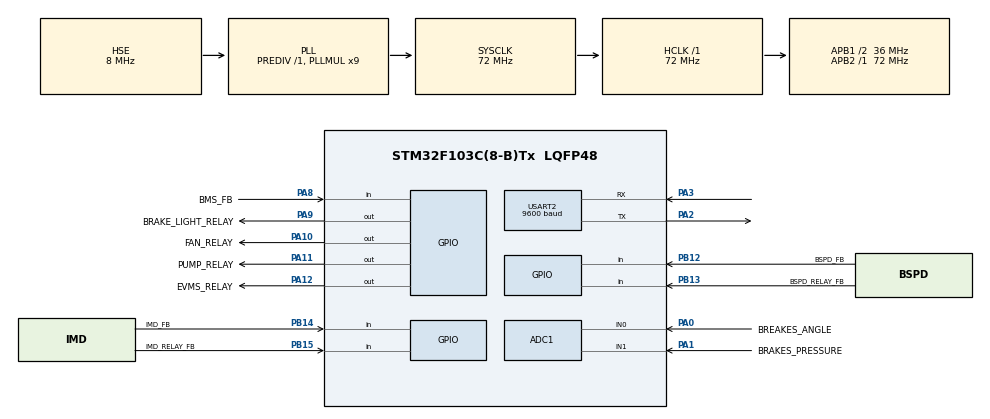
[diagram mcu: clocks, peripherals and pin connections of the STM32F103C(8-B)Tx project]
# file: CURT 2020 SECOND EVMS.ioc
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ADC1.Channel-0\#ChannelRegularConversion=ADC_CHANNEL_0
ADC1.Channel-1\#ChannelRegularConversion=ADC_CHANNEL_1
ADC1.ContinuousConvMode=ENABLE
ADC1.NbrOfConversion=2
ADC1.NbrOfConversionFlag=1
ADC1.Rank-0\#ChannelRegularConversion=1
ADC1.Rank-1\#ChannelRegularConversion=2
ADC1.SamplingTime-0\#ChannelRegularConversion=ADC_SAMPLETIME_71CYCLES_5
ADC1.SamplingTime-1\#ChannelRegularConversion=ADC_SAMPLETIME_71CYCLES_5
ADC1.master=1
Dma.ADC1.0.Direction=DMA_PERIPH_TO_MEMORY
Dma.ADC1.0.Instance=DMA1_Channel1
Dma.ADC1.0.MemDataAlignment=DMA_MDATAALIGN_HALFWORD
Dma.ADC1.0.MemInc=DMA_MINC_ENABLE
Dma.ADC1.0.Mode=DMA_CIRCULAR
Dma.ADC1.0.PeriphDataAlignment=DMA_PDATAALIGN_HALFWORD
Dma.ADC1.0.PeriphInc=DMA_PINC_DISABLE
Dma.ADC1.0.Priority=DMA_PRIORITY_LOW
Dma.Request0=ADC1
Mcu.Family=STM32F1
Mcu.Name=STM32F103C(8-B)Tx
Mcu.Package=LQFP48
NVIC.DMA1_Channel1_IRQn=true\:0\:0\:false\:false\:true\:false\:true
NVIC.PriorityGroup=NVIC_PRIORITYGROUP_4
PA0-WKUP.GPIO_Label=BREAKES_ANGLE
PA0-WKUP.Signal=ADCx_IN0
PA1.GPIO_Label=BRAKES_PRESSURE
PA1.Signal=ADCx_IN1
PA10.GPIO_Label=FAN_RELAY
PA10.Signal=GPIO_Output
PA11.GPIO_Label=PUMP_RELAY
PA11.Signal=GPIO_Output
PA12.GPIO_Label=EVMS_RELAY
PA12.Signal=GPIO_Output
PA2.Mode=Asynchronous
PA2.Signal=USART2_TX
PA3.Mode=Asynchronous
PA3.Signal=USART2_RX
PA8.GPIO_Label=BMS_FB
PA8.Signal=GPIO_Input
PA9.GPIO_Label=BRAKE_LIGHT_RELAY
PA9.Signal=GPIO_Output
PB12.GPIO_Label=BSPD_FB
PB12.Signal=GPIO_Input
PB13.GPIO_Label=BSPD_RELAY_FB
PB13.Signal=GPIO_Input
PB14.GPIO_Label=IMD_FB
PB14.Signal=GPIO_Input
PB15.GPIO_Label=IMD_RELAY_FB
PB15.Signal=GPIO_Input
PC14-OSC32_IN.Mode=LSE-External-Oscillator
PC14-OSC32_IN.Signal=RCC_OSC32_IN
PC15-OSC32_OUT.Mode=LSE-External-Oscillator
PC15-OSC32_OUT.Signal=RCC_OSC32_OUT
PD0-OSC_IN.Mode=HSE-External-Oscillator
PD0-OSC_IN.Signal=RCC_OSC_IN
PD1-OSC_OUT.Mode=HSE-External-Oscillator
PD1-OSC_OUT.Signal=RCC_OSC_OUT
ProjectManager.HeapSize=0x200
ProjectManager.StackSize=0x400
ProjectManager.TargetToolchain=TrueSTUDIO
RCC.ADCPresc=RCC_ADCPCLK2_DIV8
RCC.AHBFreq_Value=72000000
RCC.APB1CLKDivider=RCC_HCLK_DIV2
RCC.APB1Freq_Value=36000000
RCC.APB1TimFreq_Value=72000000
RCC.APB2Freq_Value=72000000
RCC.APB2TimFreq_Value=72000000
RCC.HCLKFreq_Value=72000000
RCC.PLLMUL=RCC_PLL_MUL9
RCC.PLLSourceVirtual=RCC_PLLSOURCE_HSE
RCC.SYSCLKFreq_VALUE=72000000
RCC.SYSCLKSource=RCC_SYSCLKSOURCE_PLLCLK
RCC.USBFreq_Value=72000000
SH.ADCx_IN0.0=ADC1_IN0,IN0
SH.ADCx_IN1.0=ADC1_IN1,IN1
USART2.BaudRate=9600
USART2.VirtualMode=VM_ASYNC
VP_SYS_VS_ND.Mode=No_Debug
board=custom

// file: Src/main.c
/* USER CODE BEGIN Header */
/**
  ******************************************************************************
  * @file           : main.c
  * @brief          : Main program body
  ******************************************************************************
  * @attention
  *
  * <h2><center>&copy; Copyright (c) 2021 STMicroelectronics.
  * All rights reserved.</center></h2>
  *
  * This software component is licensed by ST under BSD 3-Clause license,
  * the "License"; You may not use this file except in compliance with the
  * License. You may obtain a copy of the License at:
  *                        opensource.org/licenses/BSD-3-Clause
  *
  ******************************************************************************
  */
/* USER CODE END Header */

#include "main.h"
#include "EVMS2.h"

ADC_HandleTypeDef hadc1;
DMA_HandleTypeDef hdma_adc1;

UART_HandleTypeDef huart2;

void SystemClock_Config(void);
static void MX_GPIO_Init(void);
static void MX_ADC1_Init(void);
static void MX_USART2_UART_Init(void);
static void MX_DMA_Init(void);

int main(void)
{

  /* MCU Configuration--------------------------------------------------------*/

  /* Reset of all peripherals, Initializes the Flash interface and the Systick. */
  HAL_Init();

  /* Configure the system clock */
  SystemClock_Config();

  /* Initialize all configured peripherals */
  MX_GPIO_Init();
  MX_ADC1_Init();
  MX_USART2_UART_Init();
  MX_DMA_Init();

  /* Infinite loop */
  /* USER CODE BEGIN WHILE */
  EVMS2_init();
  while (1)
  {
    /* USER CODE END WHILE */
    loop();
  }
}

void SystemClock_Config(void)
{
  RCC_OscInitTypeDef RCC_OscInitStruct = {0};
  RCC_ClkInitTypeDef RCC_ClkInitStruct = {0};
  RCC_PeriphCLKInitTypeDef PeriphClkInit = {0};

  /** Initializes the CPU, AHB and APB busses clocks
  */
  RCC_OscInitStruct.OscillatorType = RCC_OSCILLATORTYPE_HSE;
  RCC_OscInitStruct.HSEState = RCC_HSE_ON;
  RCC_OscInitStruct.HSEPredivValue = RCC_HSE_PREDIV_DIV1;
  RCC_OscInitStruct.HSIState = RCC_HSI_ON;
  RCC_OscInitStruct.PLL.PLLState = RCC_PLL_ON;
  RCC_OscInitStruct.PLL.PLLSource = RCC_PLLSOURCE_HSE;
  RCC_OscInitStruct.PLL.PLLMUL = RCC_PLL_MUL9;
  if (HAL_RCC_OscConfig(&RCC_OscInitStruct) != HAL_OK)
  {
    Error_Handler();
  }
  /** Initializes the CPU, AHB and APB busses clocks
  */
  RCC_ClkInitStruct.ClockType = RCC_CLOCKTYPE_HCLK|RCC_CLOCKTYPE_SYSCLK
                              |RCC_CLOCKTYPE_PCLK1|RCC_CLOCKTYPE_PCLK2;
  RCC_ClkInitStruct.SYSCLKSource = RCC_SYSCLKSOURCE_PLLCLK;
  RCC_ClkInitStruct.AHBCLKDivider = RCC_SYSCLK_DIV1;
  RCC_ClkInitStruct.APB1CLKDivider = RCC_HCLK_DIV2;
  RCC_ClkInitStruct.APB2CLKDivider = RCC_HCLK_DIV1;

  if (HAL_RCC_ClockConfig(&RCC_ClkInitStruct, FLASH_LATENCY_2) != HAL_OK)
  {
    Error_Handler();
  }
  PeriphClkInit.PeriphClockSelection = RCC_PERIPHCLK_ADC;
  PeriphClkInit.AdcClockSelection = RCC_ADCPCLK2_DIV8;
  if (HAL_RCCEx_PeriphCLKConfig(&PeriphClkInit) != HAL_OK)
  {
    Error_Handler();
  }
}

static void MX_ADC1_Init(void)
{

  ADC_ChannelConfTypeDef sConfig = {0};

  /** Common config
  */
  hadc1.Instance = ADC1;
  hadc1.Init.ScanConvMode = ADC_SCAN_ENABLE;
  hadc1.Init.ContinuousConvMode = ENABLE;
  hadc1.Init.DiscontinuousConvMode = DISABLE;
  hadc1.Init.ExternalTrigConv = ADC_SOFTWARE_START;
  hadc1.Init.DataAlign = ADC_DATAALIGN_RIGHT;
  hadc1.Init.NbrOfConversion = 2;
  if (HAL_ADC_Init(&hadc1) != HAL_OK)
  {
    Error_Handler();
  }
  /** Configure Regular Channel
  */
  sConfig.Channel = ADC_CHANNEL_0;
  sConfig.Rank = ADC_REGULAR_RANK_1;
  sConfig.SamplingTime = ADC_SAMPLETIME_71CYCLES_5;
  if (HAL_ADC_ConfigChannel(&hadc1, &sConfig) != HAL_OK)
  {
    Error_Handler();
  }
  /** Configure Regular Channel
  */
  sConfig.Channel = ADC_CHANNEL_1;
  sConfig.Rank = ADC_REGULAR_RANK_2;
  if (HAL_ADC_ConfigChannel(&hadc1, &sConfig) != HAL_OK)
  {
    Error_Handler();
  }

}

static void MX_USART2_UART_Init(void)
{

  huart2.Instance = USART2;
  huart2.Init.BaudRate = 9600;
  huart2.Init.WordLength = UART_WORDLENGTH_8B;
  huart2.Init.StopBits = UART_STOPBITS_1;
  huart2.Init.Parity = UART_PARITY_NONE;
  huart2.Init.Mode = UART_MODE_TX_RX;
  huart2.Init.HwFlowCtl = UART_HWCONTROL_NONE;
  huart2.Init.OverSampling = UART_OVERSAMPLING_16;
  if (HAL_UART_Init(&huart2) != HAL_OK)
  {
    Error_Handler();
  }

}

static void MX_DMA_Init(void)
{

  /* DMA controller clock enable */
  __HAL_RCC_DMA1_CLK_ENABLE();

  /* DMA interrupt init */
  /* DMA1_Channel1_IRQn interrupt configuration */
  HAL_NVIC_SetPriority(DMA1_Channel1_IRQn, 7, 7);
  HAL_NVIC_EnableIRQ(DMA1_Channel1_IRQn);

}

static void MX_GPIO_Init(void)
{
  GPIO_InitTypeDef GPIO_InitStruct = {0};

  /* GPIO Ports Clock Enable */
  __HAL_RCC_GPIOC_CLK_ENABLE();
  __HAL_RCC_GPIOD_CLK_ENABLE();
  __HAL_RCC_GPIOA_CLK_ENABLE();
  __HAL_RCC_GPIOB_CLK_ENABLE();

  /*Configure GPIO pin Output Level */
  HAL_GPIO_WritePin(GPIOA, BRAKE_LIGHT_RELAY_Pin|FAN_RELAY_Pin|PUMP_RELAY_Pin|EVMS_RELAY_Pin, GPIO_PIN_RESET);

  /*Configure GPIO pins : BSPD_FB_Pin BSPD_RELAY_FB_Pin IMD_FB_Pin IMD_RELAY_FB_Pin */
  GPIO_InitStruct.Pin = BSPD_FB_Pin|BSPD_RELAY_FB_Pin|IMD_FB_Pin|IMD_RELAY_FB_Pin;
  GPIO_InitStruct.Mode = GPIO_MODE_INPUT;
  GPIO_InitStruct.Pull = GPIO_NOPULL;
  HAL_GPIO_Init(GPIOB, &GPIO_InitStruct);

  /*Configure GPIO pin : BMS_FB_Pin */
  GPIO_InitStruct.Pin = BMS_FB_Pin;
  GPIO_InitStruct.Mode = GPIO_MODE_INPUT;
  GPIO_InitStruct.Pull = GPIO_NOPULL;
  HAL_GPIO_Init(BMS_FB_GPIO_Port, &GPIO_InitStruct);

  /*Configure GPIO pins : BRAKE_LIGHT_RELAY_Pin FAN_RELAY_Pin PUMP_RELAY_Pin EVMS_RELAY_Pin */
  GPIO_InitStruct.Pin = BRAKE_LIGHT_RELAY_Pin|FAN_RELAY_Pin|PUMP_RELAY_Pin|EVMS_RELAY_Pin;
  GPIO_InitStruct.Mode = GPIO_MODE_OUTPUT_PP;
  GPIO_InitStruct.Pull = GPIO_NOPULL;
  GPIO_InitStruct.Speed = GPIO_SPEED_FREQ_LOW;
  HAL_GPIO_Init(GPIOA, &GPIO_InitStruct);

}

void Error_Handler(void)
{
}

/************************ (C) COPYRIGHT STMicroelectronics *****END OF FILE****/
